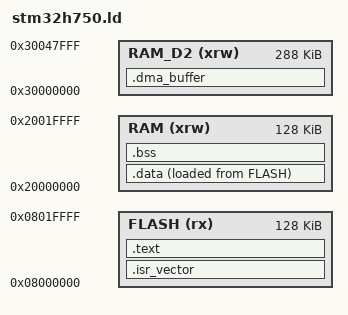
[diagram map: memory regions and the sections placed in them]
MEMORY
{
  FLASH (rx) : ORIGIN = 0x08000000, LENGTH = 128K
  RAM (xrw)  : ORIGIN = 0x20000000, LENGTH = 128K
  RAM_D2 (xrw) : ORIGIN = 0x30000000, LENGTH = 288K
}

_estack = ORIGIN(RAM) + LENGTH(RAM);

SECTIONS
{
  .isr_vector :
  {
    . = ALIGN(4);
    KEEP(*(.isr_vector))
    . = ALIGN(4);
  } > FLASH

  .text :
  {
    . = ALIGN(4);
    *(.text*)
    *(.rodata*)
    . = ALIGN(4);
    _etext = .;
  } > FLASH

  _sidata = LOADADDR(.data);

  .data :
  {
    . = ALIGN(4);
    _sdata = .;
    *(.data*)
    . = ALIGN(4);
    _edata = .;
  } > RAM AT > FLASH

  .bss :
  {
    . = ALIGN(4);
    _sbss = .;
    *(.bss*)
    *(COMMON)
    . = ALIGN(4);
    _ebss = .;
  } > RAM

  .dma_buffer (NOLOAD) :
  {
    . = ALIGN(32);
    *(.dma_buffer)
    . = ALIGN(32);
  } > RAM_D2
}
